# MEC1701Q register map
Vendor: Microchip Technology; Series: MEC1701; File version: 0
CPU: CM4 r1p0, little endian, MPU, FPU, 3 interrupt priority bits
Registers are 32-bit, read-write, reset 0x0 unless marked. A register's access mark holds for its fields unless they carry their own. Offsets are from the block's base; [hi:lo] are bit positions; {n}, {i} and the like mark numbered series.

## PECI — The PECI Interface allows the EC to retrieve temperature readings from PECI-compliant devices.
Base 0x40006400; register names take the prefix PECI_
0x00 WDATA 8-bit — The Write Data Register provides access to a 32-byte Transmit FIFO.
0x04 RDATA 8-bit — The Read Data Register provides access to a 32-byte Receive FIFO.
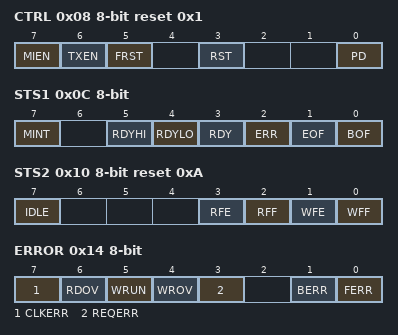
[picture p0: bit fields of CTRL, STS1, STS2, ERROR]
0x08 CTRL 8-bit reset 0x1 — Control Register
  [7] MIEN — MIEN is the Master Interrupt Enable
  [6] TXEN — TXEN is the Transmit Enable bit.
  [5] FRST — FRST is the FIFO Reset bit.
  [3] RST — RST indicates that the PECI Core should be reset.
  [0] PD — PD (Power Down) along with RST controls the Power Management Interface
0x0C STS1 8-bit — Status Register 1
  [7] MINT — MINT is the Master Interrupt Status bit and is asserted when any interrupt status bit in the Interrupt Interface is asserted.
  [5] RDYHI — RDYHI is asserted '1' on the rising edge of the READY signal function (R/WC)
  [4] RDYLO — RDYLO is asserted '1' on the falling edge of the READY signal function (R/WC)
  [3] RDY — RDY represents the state of the READY signal function
  [2] ERR — ERR Indicates that an error for the current transaction has been detected.
  [1] EOF — EOF (End of Frame) is asserted following Message Stop (tSTOP). (R/WC)
  [0] BOF — BOF (Beginning of Frame) is asserted when the PECI Core begins Address Timing Negotiation. (R/WC)
0x10 STS2 8-bit ro reset 0xA — Status Register 2
  [7] IDLE — The IDLE status bit indicates when the SST/PECI bus is idle and a new transaction may begin.
  [3] RFE — RFE indicates that the Read Data Register FIFO is empty. RFE does not generate an interrupt.
  [2] RFF — RFF indicates that the Read Data Register FIFO is full.
  [1] WFE — WFE indicates that the Write Data Register FIFO is empty.
  [0] WFF — WFF indicates that the Write Data Register FIFO is full. WFF does not generate an interrupt.
0x14 ERROR 8-bit
  [7] CLKERR — CLKERR indicates that the READY signal function in the Hardware Interface was de-asserted in the middle of a transaction (R/WC)
  [6] RDOV — RDOV (Read Overrun). RDOV indicates that the internal read buffer has overflowed (R/WC)
  [5] WRUN — WRUN (Write Underrun). (R/WC)
  [4] WROV — WROV (Write Overrun). (R/WC)
  [3] REQERR — REQERR is asserted if PEC_AVAILABLE (READY) input is not asserted when the counts down to zero as shown in. When asserted, REQERR can generate interrupt. (R/WC)
  [1] BERR — BERR (Bus Error). Bus contention has been detected. BERR is asserted when the PECI Module reads a value that is different from what it has driven (R/WC)
  [0] FERR — FERR (Frame Check Sequence Error). (R/WC)
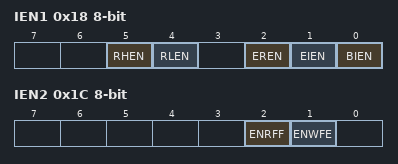
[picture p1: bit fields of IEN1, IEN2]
0x18 IEN1 8-bit — Interrupt Enable 1 Register
  [5] RHEN — When the RHEN bit is asserted '1' the RDYHI interrupt is enabled.
  [4] RLEN — When the RLEN bit is asserted '1' the RDYLO interrupt is enabled.
  [2] EREN — When the EREN bit is asserted '1' the ERR interrupt is enabled.
  [1] EIEN — When the EIEN bit is asserted '1' the EOF interrupt is enabled.
  [0] BIEN — When the BIEN bit is asserted '1' the BOF interrupt is enabled.
0x1C IEN2 8-bit — Interrupt Enable 2 Register
  [2] ENRFF — When the ENRFF bit is asserted '1' the RFF interrupt is enabled.
  [1] ENWFE — When the ENWFE bit is asserted '1' the WFE interrupt is enabled.
0x20 OPTBTLO 8-bit reset 0x16 — Optimal Bit Time Register (Low Byte)
0x24 OPTBTHI 8-bit — Optimal Bit Time Register (High Byte)
0x30 BDCTRL reset 0x6 — Baud Control Register. The baud div value divides down the sytem clock frequency to create the peci CORE_CLK frequency.
0x40 BLKID reset 0xF — Block BLKID Register
0x44 BLKREV reset 0xF — Revision Register

## MBX — The Mailbox provides a standard run-time mechanism for the host to communicate with the Embedded Controller (EC).
Base 0x400F0000; register names take the prefix MBX_
0x00 RT_IDX 8-bit — MBX_Index Register
0x01 RT_DATA 8-bit — MBX_Data_Register
0x100 H2EC — If enabled, an interrupt to the EC marked by the MBX_DATA bit in the Interrupt Aggregator will be generated whenever the Host writes this register. This register is cleared when written with FFh.
0x104 EC2H 8-bit — An EC write to this register will set bit EC_WR in the SMI Interrupt Source Register to '1b'. If enabled, this will generate a Host SMI. This register is cleared when written with FFh.
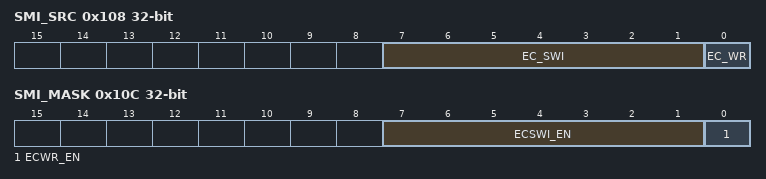
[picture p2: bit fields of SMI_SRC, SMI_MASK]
0x108 SMI_SRC — SMI Interrupt Source Register
  [7:1] EC_SWI — EC Software Interrupt. An SIRQ to the Host is generated when any bit in this register when this bit is set to '1b' and the corresponding bit in the SMI Interrupt Mask Register register is '1b'.
  [0] EC_WR — EC Mailbox Write. This bit is set automatically when the EC-to-Host Mailbox Register has been written. An SMI or SIRQ to the Host is generated when n this bit is '1b' and the corresponding bit in the SMI Interrupt Mask Register register is '1b'. This bit is automatically cleared by a read of the EC-to-Host Mailbox Register through the Host Access Port.
0x10C SMI_MASK — SMI Interrupt Mask Register
  [7:1] ECSWI_EN — EC Software Interrupt Enable. If this bit is '1b', the bit EC_WR in the SMI Interrupt Source Register is enabled for the generation of SIRQ or nSMI events.
  [0] ECWR_EN — EC Mailbox Write.Interrupt Enable. Each bit in this field that is '1b' enables the generation of SIRQ interrupts when the corresponding bit in the EC_SWI field in the SMI Interrupt Source Register is '1b'.
{0x110+4i} MBX_REG[{i}] (i=0..7) — Mailbox Register
